# CLK1_FLAGMUX_CLK1 register map
Vendor: Texas Instruments
Peripheral module from a debugger description file (folder omap4430).
Registers are 32-bit, read-only, reset 0x0 unless marked. A register's access mark holds for its fields unless they carry their own. Offsets are as the file gives them; lines under a group give offsets from that group; [hi:lo] are bit positions; {n}, {i} and the like mark numbered series; 'fields as' and 'values as' point back to an identical list; <NAME> marks a mode.

## CLK1_FLAGMUX_CLK1
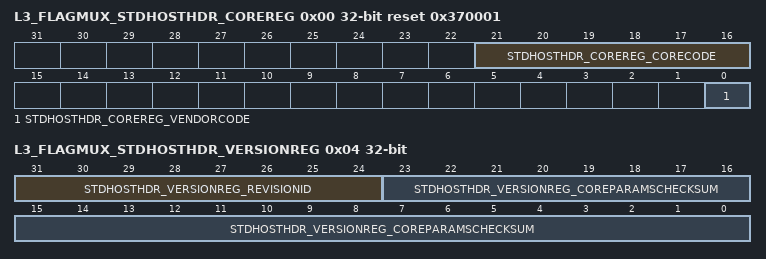
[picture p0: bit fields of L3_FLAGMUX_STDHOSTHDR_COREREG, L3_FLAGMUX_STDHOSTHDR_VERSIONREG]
0x00 L3_FLAGMUX_STDHOSTHDR_COREREG reset 0x370001
  [21:16] STDHOSTHDR_COREREG_CORECODE — The Core Code field is a constant reporting a vendor-specific core generator code. Type: Constant. Reset value: 0x37.
  [0] STDHOSTHDR_COREREG_VENDORCODE — The Vendor Code field is a constant reporting the core generator vendor code. Type: Constant. Reset value: 0x1.
    0=STDHOSTHDR_COREREG_VENDORCODE_0_r (Third-party vendor.); 1=STDHOSTHDR_COREREG_VENDORCODE_1_r
0x04 L3_FLAGMUX_STDHOSTHDR_VERSIONREG
  [31:24] STDHOSTHDR_VERSIONREG_REVISIONID — The Revision Identifier field is a constant reporting the core generator revision number. Type: Constant. Reset value: 0x0.
  [23:0] STDHOSTHDR_VERSIONREG_COREPARAMSCHECKSUM — Reserved. Type: Reserved. Reset value: Reserved.
0x08 L3_FLAGMUX_MASK0 access per field reset 0x3FFFF
  [17:0] MASK0 rw — Mask flag inputs 0 Type: Control. Reset value: 0x3FFFF.
0x0C L3_FLAGMUX_REGERR0
  [17:0] REGERR0 — Flag inputs 0 Type: Status. Reset value: X.
0x10 L3_FLAGMUX_MASK1 access per field reset 0x3FFFF
  [17:0] MASK1 rw — Mask flag inputs 1 Type: Control. Reset value: 0x3FFFF.
0x14 L3_FLAGMUX_REGERR1
  [17:0] REGERR1 — Flag inputs 1 Type: Status. Reset value: X.
